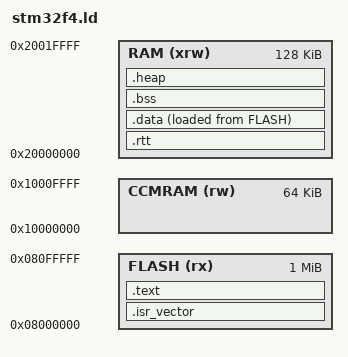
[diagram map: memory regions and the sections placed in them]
/* stm32f4.ld */
ENTRY(Reset_Handler)

/* Highest address of the user mode stack */
_estack = 0x20020000;    /* end of RAM (128K SRAM) */

MEMORY
{
  FLASH (rx)      : ORIGIN = 0x08000000, LENGTH = 1024K
  RAM (xrw)       : ORIGIN = 0x20000000, LENGTH = 128K
  CCMRAM (rw)     : ORIGIN = 0x10000000, LENGTH = 64K
}

SECTIONS
{
  /* The startup code goes first into FLASH */
  .isr_vector :
  {
    . = ALIGN(4);
    KEEP(*(.vectors)) /* Startup code */
    . = ALIGN(4);
  } >FLASH

  /* The program code and other data goes into FLASH */
  .text :
  {
    . = ALIGN(4);
    *(.text)           /* .text sections (code) */
    *(.text*)          /* .text* sections (code) */
    *(.rodata)         /* .rodata sections (constants, strings, etc.) */
    *(.rodata*)        /* .rodata* sections (constants, strings, etc.) */
    . = ALIGN(4);
    _etext = .;        /* define a global symbols at end of code */
  } >FLASH

  /* Used by the startup to initialize data */
  _sidata = LOADADDR(.data);

  /* RTT Control Block and Buffers - placed at the start of RAM for reliable J-Link discovery */
  .rtt (NOLOAD) :
  {
    . = ALIGN(4);
    *(.rtt)
    . = ALIGN(4);
  } >RAM

  /* Initialized data sections goes into RAM, load LMA copy after code */
  .data :
  {
    . = ALIGN(4);
    _sdata = .;        /* create a global symbol at data start */
    *(.data)           /* .data sections */
    *(.data*)          /* .data* sections */
    . = ALIGN(4);
    _edata = .;        /* define a global symbol at data end */
  } >RAM AT> FLASH

  /* Uninitialized data section */
  .bss :
  {
    /* This is used by the startup in order to initialize the .bss secion */
    . = ALIGN(4);
    _sbss = .;         /* define a global symbol at bss start */
    __bss_start__ = _sbss;
    *(.bss)
    *(.bss*)
    *(COMMON)

    . = ALIGN(4);
    _ebss = .;         /* define a global symbol at bss end */
    __bss_end__ = _ebss;
  } >RAM

  /* User heap section, used by sbrk */
  .heap :
  {
    . = ALIGN(4);
    PROVIDE ( end = . );
    PROVIDE ( _end = . );
    . = . + 0x1000; /* Minimal heap of 4KB */
    . = ALIGN(4);
  } >RAM
}
